# STM32MP13xx register map
File version: 1.7
CPU: CA7 r0p0, little endian, MPU, FPU, 4 interrupt priority bits
Registers are 32-bit, read-write, reset 0x0 unless marked. A register's access mark holds for its fields unless they carry their own. Offsets are from the block's base; [hi:lo] are bit positions; lines under a group give offsets from that group; {n}, {i} and the like mark numbered series; 'fields as' and 'values as' point back to an identical list.

## GICD — GICD address block description
Base 0xA0021000
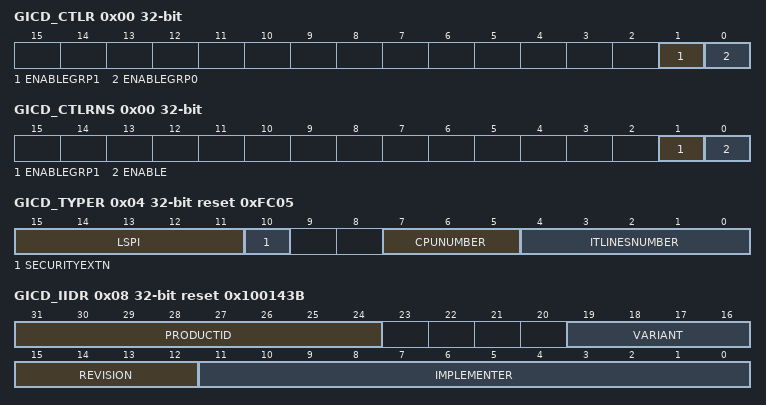
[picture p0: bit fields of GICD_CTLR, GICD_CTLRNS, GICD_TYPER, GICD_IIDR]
0x00 GICD_CTLR
  [1] ENABLEGRP1 — enable group 1 interrupts Global enable for forwarding pending group 1 interrupts from the GICD to the CPU interfaces
  [0] ENABLEGRP0 — enable group 1 interrupts Global enable for forwarding pending group 1 interrupts from the GICD to the CPU interfaces
0x00 GICD_CTLRNS (alternate view of GICD_CTLR)
  [1] ENABLEGRP1 — enable group 1 interrupts Global enable for forwarding pending group 1 interrupts from the GICD to the CPU interfaces
  [0] ENABLE — Global enable for forwarding pending group 1 interrupts from the GICD to the CPU interfaces
0x04 GICD_TYPER ro reset 0xFC05
  [15:11] LSPI — lockable shared peripheral interrupt Returns the number of LSPIs that the interrupt controller contains (0b1111 = 31 LSPIs, these are the interrupts of IDs 32-62).
  [10] SECURITYEXTN — security extension Indicates whether the GIC implements the security extensions. This bit always returns a value of 1, indicating that the security extensions are implemented.
  [7:5] CPUNUMBER — number of processors interfaces Indicates the number of implemented processors interfaces in the GIC (0b000 = 1 processor)
  [4:0] ITLINESNUMBER — number of interrupt lines Indicates the number of interrupts that the GIC supports (0b00101 = Up to 192 interrupts, 160 external interrupts)
0x08 GICD_IIDR ro reset 0x100143B
  [31:24] PRODUCTID — product ID of the GIC
  [19:16] VARIANT — Indicates the major revision number of the GIC
  [15:12] REVISION — Indicates the minor revision number of the GIC
  [11:0] IMPLEMENTER — GIC implementer (0x43B Arm implementation)
{0x80+4i} GICD_IGROUPR{i} (i=0..5) — GICD interrupt group register {i}
  [31:0] IGROUPRx — group of interrupts
0x100 GICD_ISENABLER0 — GICD interrupt set-enable register
  [31:0] ISENABLER0 — interrupt set-enable 0
{0x100+4i} GICD_ISENABLER{i} (i=1..5) — GICD interrupt set-enable register {i}
  [31:0] ISENABLERx — interrupt set-enable x
0x180 GICD_ICENABLER0 — GICD interrupt clear-enable register
  [31:0] ICENABLER0 — interrupt clear-enable 0
{0x180+4i} GICD_ICENABLER{i} (i=1..5) — GICD interrupt clear-enable register {i}
  [31:0] ICENABLERx — interrupt clear-enable x
{0x200+4i} GICD_ISPENDR{i} (i=0..5) — GICD interrupt set-pending register {i}
  [31:0] ISPENDRx — interrupt set-pending x
{0x280+4i} GICD_ICPENDR{i} (i=0..5) — GICD interrupt clear-pending register {i}
  [31:0] ICPENDRx — interrupt clear-pending x
{0x300+4i} GICD_ISACTIVER{i} (i=0..5) — GICD interrupt set-active register {i}
  [31:0] ISACTIVERx — interrupt set-active x
{0x380+4i} GICD_ICACTIVER{i} (i=0..5) — GICD interrupt clear-active register {i}
  [31:0] ICACTIVERx — interrupt clear-active x
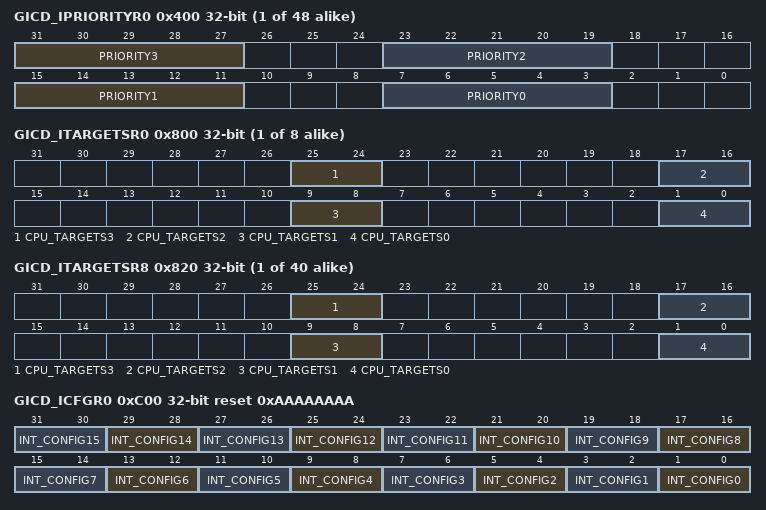
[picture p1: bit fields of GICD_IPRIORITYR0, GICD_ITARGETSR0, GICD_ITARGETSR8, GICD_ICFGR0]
{0x400+4i} GICD_IPRIORITYR{i} (i=0..47)
  [31:27] PRIORITY3 — priority for interrupt ID = x * 4 + 3
  [23:19] PRIORITY2 — priority for interrupt ID = x * 4 + 2
  [15:11] PRIORITY1 — priority for interrupt ID = x * 4 + 1
  [7:3] PRIORITY0 — priority for interrupt ID = x * 4
{0x800+4i} GICD_ITARGETSR{i} ro reset not defined (i=0..7) — GICD interrupt processor target register {i}
  [25:24] CPU_TARGETS3 — CPU(s) target for interrupt ID = x * 4 + 3
  [17:16] CPU_TARGETS2 — CPU(s) target for interrupt ID = x * 4 + 2
  [9:8] CPU_TARGETS1 — CPU(s) target for interrupt ID = x * 4 + 1
  [1:0] CPU_TARGETS0 — CPU(s) target for interrupt ID = x * 4
{0x800+4i} GICD_ITARGETSR{i} (i=8..47)
  fields as GICD_ITARGETSR0
0xC00 GICD_ICFGR0 reset 0xAAAAAAAA
  [2n+1:2n] INT_CONFIG{n} (n=0..15) — interrupt config for interrupt ID = {n}
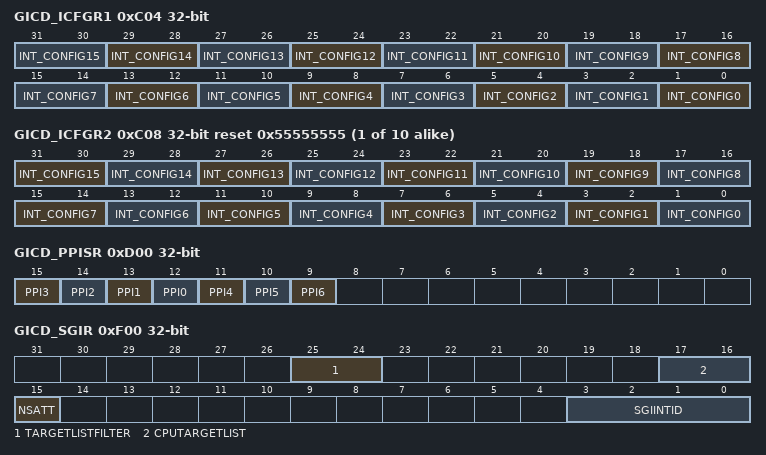
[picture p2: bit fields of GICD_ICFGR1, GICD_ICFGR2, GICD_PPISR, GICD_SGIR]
0xC04 GICD_ICFGR1 — GICD interrupt configuration register
  [2n+1:2n] INT_CONFIG{n} (n=0..15) — interrupt config for interrupt ID = {n+16}
{0xC00+4i} GICD_ICFGR{i} reset 0x55555555 (i=2..11)
  [2n+1:2n] INT_CONFIG{n} (n=1..15) — interrupt config for interrupt ID = x * 16 + {n}
  [1:0] INT_CONFIG0 — interrupt config for interrupt ID = x * 16
0xD00 GICD_PPISR ro
  [15] PPI3 — nIRQ (not used)
  [14] PPI2 — secure physical timer event
  [13] PPI1 — secure physical timer event
  [12] PPI0 — nFIQ (not used)
  [11] PPI4 — virtual timer event
  [10] PPI5 — hypervisor timer event
  [9] PPI6 — virtual maintenance interrupt
{0xD04+4i} GICD_SPISR{i} ro (i=0..4) — GICD shared peripheral interrupt register {i}
  [31:0] SPISRx — shared peripheral interrupt
0xF00 GICD_SGIR wo reset not defined
  [25:24] TARGETLISTFILTER — target list filter Determines how the distributor must process the requested SGI 2: Forward the interrupt only to the CPU interface of the processor which requested the interrupt 3: Reserved, must be kept at reset value.
    0=Forward the interrupt to the CPU interfaces specified in the CPUTARGETLIST field; 1=Forward the interrupt to all CPU interfaces except the processor which requested the interrupt
  [17:16] CPUTARGETLIST — CPU target list When TARGETLISTFILTER = 0b00, defines the CPU interfaces to which the GICD must forward the interrupt. Each bit of CPUTARGETLIST[1:0] refers to the corresponding CPU interface. If this field is 0 when TARGETLISTFILTER is 0b00, the GICD does not forward the interrupt to any CPU interface.
  [15] NSATT — non-secure attribute It specifies the required security value of the SGI: 0 - Forward the SGI specified in the SGIINTID field to a specified CPU interface only if the SGI is configured as group 0 on that interface. 1 - Forward the SGI specified in the SGIINTID field to a specified CPU interfaces only if the SGI is configured as group 1 on that interface. This field is writable only by a secure access. Any non-secure write to the GICD_SGIR generates an SGI only if the specified SGI is programmed as group 1.
  [3:0] SGIINTID — SGI interrupt ID The value of this field is the interrupt ID of the SGI to forward to the specified CPU interfaces, in the range 0-15 (for example: a value of 0b0011 specifies interrupt ID 3).
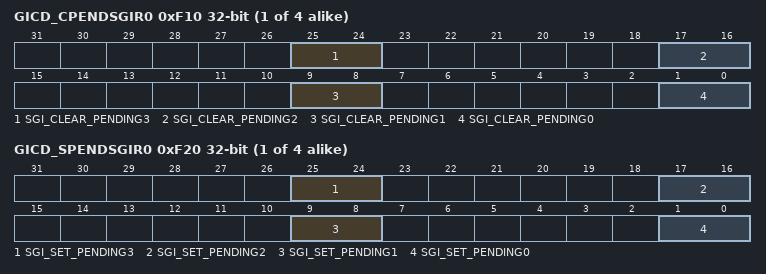
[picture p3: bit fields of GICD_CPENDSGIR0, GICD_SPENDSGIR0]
{0xF10+4i} GICD_CPENDSGIR{i} (i=0..3) — GICD SGI clear-pending register {i}
  [25:24] SGI_CLEAR_PENDING3 — clear-pending state for SGI [x * 4 + 3] Writing a 1 clears the pending state of the SGI [x * 4 + 3] for the corresponding source processor, and no longer targets the processor performing the write. Writing a 0 has no effect. Reading a bit identifies whether the SGI [x * 4 + 3] is pending, from the corresponding source processor, on the reading processor.
  [17:16] SGI_CLEAR_PENDING2 — clear-pending state for SGI [x * 4 + 2] Writing a 1 clears the pending state of the SGI [x * 4 + 2] for the corresponding source processor, and no longer targets the processor performing the write. Writing a 0 has no effect. Reading a bit identifies whether the SGI [x * 4 + 2] is pending, from the corresponding source processor, on the reading processor.
  [9:8] SGI_CLEAR_PENDING1 — clear-pending state for SGI [x * 4 + 1] Writing a 1 clears the pending state of the SGI [x * 4 + 1] for the corresponding source processor, and no longer targets the processor performing the write. Writing a 0 has no effect. Reading a bit identifies whether the SGI [x * 4 + 1] is pending, from the corresponding source processor, on the reading processor.
  [1:0] SGI_CLEAR_PENDING0 — clear-pending state for SGI [x * 4] Writing a 1 clears the pending state of the SGI [x * 4] for the corresponding source processor, and no longer targets the processor performing the write. Writing a 0 has no effect. Reading a bit identifies whether the SGI [x * 4] is pending, from the corresponding source processor, on the reading processor.
{0xF20+4i} GICD_SPENDSGIR{i} (i=0..3) — GICD SGI set-pending register {i}
  [25:24] SGI_SET_PENDING3 — set-pending state for SGI [x * 4 + 3] Writing a 1 sets the pending state of the SGI [x * 4 + 3] for the corresponding source processor. Writing a 0 has no effect. Reading a bit identifies whether the SGI [x * 4 + 3] is pending, from the corresponding source processor, on the reading processor.
  [17:16] SGI_SET_PENDING2 — set-pending state for SGI [x * 4 + 2] Writing a 1 sets the pending state of the SGI [x * 4 + 2] for the corresponding source processor. Writing a 0 has no effect. Reading a bit identifies whether the SGI [x * 4 + 2] is pending, from the corresponding source processor, on the reading processor.
  [9:8] SGI_SET_PENDING1 — set-pending state for SGI [x * 4 + 1] Writing a 1 sets the pending state of the SGI [x * 4 + 1] for the corresponding source processor. Writing a 0 has no effect. Reading a bit identifies whether the SGI [x * 4 + 1] is pending, from the corresponding source processor, on the reading processor.
  [1:0] SGI_SET_PENDING0 — set-pending state for SGI [x * 4] Writing a 1 sets the pending state of the SGI [x * 4] for the corresponding source processor. Writing a 0 has no effect. Reading a bit identifies whether the SGI [x * 4] is pending, from the corresponding source processor, on the reading processor.
0xFD0 GICD_PIDR4 ro reset 0x4
  [31:0] PIDR4 — peripheral ID4
{0xFC0+4i} GICD_PIDR{i} ro (i=5..7)
  [31:0] PIDRx — peripheral ID5 to ID7
0xFE0 GICD_PIDR0 ro reset 0x90
  [31:0] PIDR0 — peripheral ID0
0xFE4 GICD_PIDR1 ro reset 0xB4
  [31:0] PIDR1 — peripheral ID1
0xFE8 GICD_PIDR2 ro reset 0x2B
  [31:0] PIDR2 — peripheral ID2
0xFEC GICD_PIDR3 ro
  [31:0] PIDR3 — peripheral ID3
0xFF0 GICD_CIDR0 ro reset 0xD
  [31:0] CIDR0 — component ID0
0xFF4 GICD_CIDR1 ro reset 0xF0
  [31:0] CIDR1 — component ID1
0xFF8 GICD_CIDR2 ro reset 0x5
  [31:0] CIDR2 — component ID2
0xFFC GICD_CIDR3 ro reset 0xB1
  [31:0] CIDR3 — component ID3
